# tviibh16m register map
Vendor: Infineon Technologies; Series: TVIIBH16M; File version: 1.0
CPU: CM7 r0p1, little endian, MPU, FPU, double-precision FPU, I-cache, D-cache, VTOR, ITCM, DTCM, 3 interrupt priority bits, 16 interrupts
Registers are 32-bit, read-write, reset 0x0 unless marked. A register's access mark holds for its fields unless they carry their own. Offsets are from the block's base; [hi:lo] are bit positions; lines under a group give offsets from that group; {n}, {i} and the like mark numbered series; 'fields as' and 'values as' point back to an identical list; <NAME> marks a mode.

## SRSS (part 3 of 3) — SRSS Core Registers (ver3p3)
Base 0x40260000
0x1730 CSV_ILO group — CSV registers for HVILO clock
  0x00 CSV group — ILO0 clock DeepSleep domain Clock Supervisor registers
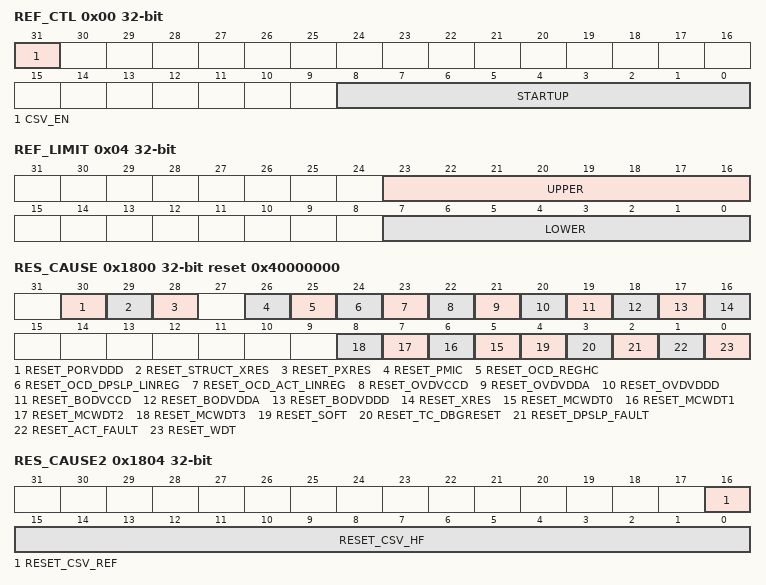
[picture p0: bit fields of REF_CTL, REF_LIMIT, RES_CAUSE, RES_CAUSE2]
    0x00 REF_CTL — Clock Supervision Reference Control
      [31] CSV_EN — Enables clock supervision, both frequency and loss. CSV in Active domain: Clock supervision is reset during DeepSleep and Hibernate modes. When enabled it begins operating automatically after a DeepSleep wakeup, but it must be reconfigured after Hibernate wakeup. CSV in DeepSleep domain: Clock supervision is reset during Hibernate mode. It must be reconfigured after Hibernate wakeup. CSV in Backup domain: Clock supervision operates during Hibernate mode, can be configured to wake from Hibernate, and continues operating during reboot. A CSV error detection is reported to the Fault structure.
      [8:0] STARTUP — Startup delay time -1 (in reference clock cycles), after enable, from reference clock start to monitored clock start. At a minimum (both clocks running): STARTUP >= (PERIOD +3) * FREQ_RATIO - UPPER, with FREQ_RATIO = (Reference frequency / Monitored frequency) On top of that the actual clock startup delay and the margin for accuracy of both clocks must be added.
    0x04 REF_LIMIT — Clock Supervision Reference Limits
      [23:16] UPPER — Cycle time upper limit. Set the upper limit -1, in reference clock cycles, before (or same time) the next monitored clock event must happen. If a monitored clock event does not happen before this limit is reached, or does not happen at all (clock loss), a CSV error is detected.
      [7:0] LOWER — Cycle time lower limit. Set the lower limit -1, in reference clock cycles, before the next monitored clock event is allowed to happen. If a monitored clock event happens before this limit is reached a CSV error is detected. LOWER must be at least 1 less than UPPER. In case the clocks are asynchronous LOWER must be at least 3 less than UPPER.
    0x08 MON_CTL — Clock Supervision Monitor Control
      [7:0] PERIOD — Period time. Set the Period -1, in monitored clock cycles, before the next monitored clock event happens. PERIOD <= (UPPER+1) / FREQ_RATIO -1, with FREQ_RATIO = (Reference frequency / Monitored frequency) In case the clocks are asynchronous: PERIOD <= UPPER / FREQ_RATIO -1 Additionally margin must be added for accuracy of both clocks.
0x1800 RES_CAUSE reset 0x40000000 — Reset Cause Observation Register
  [30] RESET_PORVDDD write-1-clears — Indicator that a POR occurred. This is a high-voltage cause bit, and hardware clears the other bits when this one is set. It does not block further recording of other high-voltage causes.
  [29] RESET_STRUCT_XRES write-1-clears — Structural reset was asserted. This is a high-voltage cause bit that blocks recording of other high-voltage cause bits, except RESET_PORVDDD. Hardware clears this bit during POR. This bit is not blocked by other HV cause bits.
  [28] RESET_PXRES write-1-clears — PXRES triggered. This is a high-voltage cause bit that blocks recording of other high-voltage cause bits, except RESET_PORVDDD. Hardware clears this bit during POR. This bit is not blocked by other HV cause bits.
  [26] RESET_PMIC write-1-clears — PMIC status triggered a reset. PMIC_STATUS_TIMEOUT expiration will set this bit without issuing reset, which will be observed by a subsequent WDT reset. If PMIC control is not present, hardware will never set this bit. This is a high-voltage cause bit that blocks recording of other high-voltage cause bits, except RESET_PORVDDD. Hardware clears this bit during POR.
  [25] RESET_OCD_REGHC write-1-clears — Overcurrent detection from REGHC (if present). REGHC_STATUS_TIMEOUT expiration will set this bit without issuing reset, which will be observed by a subsequent WDT reset. If REGHC is not present, hardware will never set this bit. This is a high-voltage cause bit that blocks recording of other high-voltage cause bits, except RESET_PORVDDD. Hardware clears this bit during POR.
  [24] RESET_OCD_DPSLP_LINREG write-1-clears — Overcurrent detection on the internal VCCD supply when supplied by the DEEPSLEEP power mode linear regulator. This is a high-voltage cause bit that blocks recording of other high-voltage cause bits, except RESET_PORVDDD. Hardware clears this bit during POR.
  [23] RESET_OCD_ACT_LINREG write-1-clears — Overcurrent detection on the internal VCCD supply when supplied by the ACTIVE power mode linear regulator. This is a high-voltage cause bit that blocks recording of other high-voltage cause bits, except RESET_PORVDDD. Hardware clears this bit during POR.
  [22] RESET_OVDVCCD write-1-clears — Overvoltage detection on the internal core VCCD supply. This is a high-voltage cause bit that blocks recording of other high-voltage cause bits, except RESET_PORVDDD. Hardware clears this bit during POR.
  [21] RESET_OVDVDDA write-1-clears — Overvoltage detection on the external VDDA supply. This is a high-voltage cause bit that blocks recording of other high-voltage cause bits, except RESET_PORVDDD. Hardware clears this bit during POR.
  [20] RESET_OVDVDDD write-1-clears — Overvoltage detection on the external VDDD supply. This is a high-voltage cause bit that blocks recording of other high-voltage cause bits, except RESET_PORVDDD. Hardware clears this bit during POR.
  [19] RESET_BODVCCD write-1-clears — Internal VCCD core supply crossed the brown-out limit. Note that this detector will detect gross issues with the internal core supply, but may not catch all brown-out conditions. Functional and timing supervision (CSV, WDT) is provided to create fully failsafe internal crash detection. This is a high-voltage cause bit that blocks recording of other high-voltage cause bits, except RESET_PORVDDD. Hardware clears this bit during POR.
  [18] RESET_BODVDDA write-1-clears — External VDDA supply crossed the brown-out limit. This is a high-voltage cause bit that blocks recording of other high-voltage cause bits, except RESET_PORVDDD. Hardware clears this bit during POR.
  [17] RESET_BODVDDD write-1-clears — External VDDD supply crossed brown-out limit. Note that this cause will only be observable as long as the VDDD supply does not go below the POR (power on reset) detection limit. Below this limit it is not possible to reliably retain information in the device. This is a high-voltage cause bit that blocks recording of other high-voltage cause bits, except RESET_PORVDDD. Hardware clears this bit during POR.
  [16] RESET_XRES write-1-clears — External XRES pin was asserted. This is a high-voltage cause bit that blocks recording of other high-voltage cause bits, except RESET_PORVDDD. Hardware clears this bit during POR. This bit is not blocked by other HV cause bits.
  [n+5] RESET_MCWDT{n} write-1-clears (n=0..3) — Multi-Counter Watchdog timer reset #{n}. This is a low-voltage cause bit that hardware clears when the low-voltage supply is initialized (see comments above).
  [4] RESET_SOFT write-1-clears — A CPU requested a system reset through it's SYSRESETREQ. This can be done via a debugger probe or in firmware. This is a low-voltage cause bit that hardware clears when the low-voltage supply is initialized (see comments above).
  [3] RESET_TC_DBGRESET write-1-clears — Test controller or debugger asserted reset. Only resets debug domain. This is a low-voltage cause bit that hardware clears when the low-voltage supply is initialized (see comments above).
  [2] RESET_DPSLP_FAULT write-1-clears — Fault logging system requested a reset from its DeepSleep logic. This is a low-voltage cause bit that hardware clears when the low-voltage supply is initialized (see comments above).
  [1] RESET_ACT_FAULT write-1-clears — Fault logging system requested a reset from its Active logic. This is a low-voltage cause bit that hardware clears when the low-voltage supply is initialized (see comments above).
  [0] RESET_WDT write-1-clears — A basic WatchDog Timer (WDT) reset has occurred since last power cycle. ULP products: This is a low-voltage cause bit that hardware clears when the low-voltage supply is initialized (see comments above). For products that support high-voltage cause detection, this bit blocks recording of other high-voltage cause bits, except RESET_PORVDDD. Hardware clears this bit during POR. This bit is not blocked by other HV cause bits.
0x1804 RES_CAUSE2 — Reset Cause Observation Register 2
  [16] RESET_CSV_REF write-1-clears — Clock supervision logic requested a reset due to loss or frequency violation of the reference clock source that is used to monitor the other HF clock sources.
  [15:0] RESET_CSV_HF write-1-clears — Clock supervision logic requested a reset due to loss or frequency violation of a high-frequency clock. Each bit index K corresponds to a HFCLK<K>. Unimplemented clock bits return zero.
{0x1900+0x10*i} CLK_PLL400M[{i}] (i=0..1) group — 400MHz PLL Configuration Register
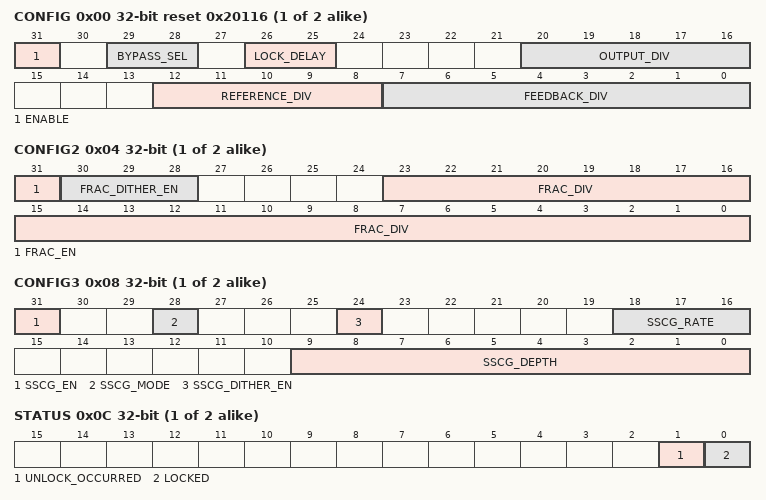
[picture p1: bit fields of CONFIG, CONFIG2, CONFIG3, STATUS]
  0x00 CONFIG reset 0x20116 — 400MHz PLL Configuration Register
    [31] ENABLE — Master enable for PLL. Setup FEEDBACK_DIV, REFERENCE_DIV, and OUTPUT_DIV at least one cycle before setting ENABLE=1. fOUT = (FEEDBACK_DIV + FRAC_EN*FRAC_DIV/2^24) * (fREF / REFERENCE_DIV) / (OUTPUT_DIV) 0: Block is disabled. When the PLL disables, hardware controls the bypass mux as described in BYPASS_SEL, before disabling the PLL circuit. 1: Block is enabled
    [29:28] BYPASS_SEL — Bypass mux located just after PLL output. This selection is glitch-free and can be changed while the PLL is running. When changing BYPASS_SEL, do not turn off the reference clock or PLL clock for five cycles (whichever is slower).
      0=AUTO (Automatic using lock indicator. When unlocked, automatically selects PLL reference input (bypass mode). When locked, automatically selects PLL output. If ENABLE=0, automatically selects PLL reference input.); 1=LOCKED_OR_NOTHING (Similar to AUTO, except the clock is gated off when unlocked. This is compatible with clock supervision, because the supervisors allow no clock during startup (until a timeout occurs), and the clock targets the proper frequency whenever it is running. If ENABLE=0, no clock is output.); 2=PLL_REF (Select PLL reference input (bypass mode). Ignores lock indicator); 3=PLL_OUT (Select PLL output. Ignores lock indicator. If ENABLE=0, no clock is output.)
    [26:25] LOCK_DELAY
    [20:16] OUTPUT_DIV — Control bits for Output divider. Set the divide value before enabling the PLL, and do not change it while PLL is enabled. 0: illegal (undefined behavior) 1: illegal (undefined behavior) 2: divide by 2. Suitable for direct usage as HFCLK source. ... 16: divide by 16. Suitable for direct usage as HFCLK source. >16: illegal (undefined behavior)
    [12:8] REFERENCE_DIV — Control bits for reference divider. Set the divide value before enabling the PLL, and do not change it while PLL is enabled. 0: illegal (undefined behavior) 1: divide by 1 ... 16: divide by 16 others: illegal (undefined behavior) When using fractional mode, the jitter specs are met over the restricted range of 1 to 4, inclusive.
    [7:0] FEEDBACK_DIV — Control bits for feedback divider. Set the divide value before enabling the PLL, and do not change it while PLL is enabled. 0-15: illegal (undefined behavior) 16: divide by 16 ... 200: divide by 200 >200: illegal (undefined behavior) When using fractional mode, the jitter specs are met over the restricted range of 27 to 47, inclusive.
  0x04 CONFIG2 — 400MHz PLL Configuration Register 2
    [31] FRAC_EN — Enables fractional division mode. When using fractional division mode, see CLK_PLL400M_CONFIG.LOCK_DELAY for an additional configuration requirement.
    [30:28] FRAC_DITHER_EN
    [23:0] FRAC_DIV — Control bits for fractional divider. This value is interpreted as a fraction of the PFD frequency, i.e. fPFD * (FRAC_DIV/2^24). This field can be dynamically updated within the 1000ppm control limit. It takes up to 115 AHB cycles to transfer the setting to the PLL, and writes that occur faster may be silently ignored and require the application to write again after the previous update has finished. Reading the register returns the accepted value. The PLL will start targeting the new value, but it may take significant time (milliseconds) to stabilize at the new average value. Do not change the FRAC_DIV setting while the PLL is initially locking.
  0x08 CONFIG3 — 400MHz PLL Configuration Register 3
    [31] SSCG_EN — Enables spreading mode. When using spreading, see CLK_PLL400M_CONFIG.LOCK_DELAY for an additional configuration requirement.
    [28] SSCG_MODE
    [24] SSCG_DITHER_EN
    [18:16] SSCG_RATE
    [9:0] SSCG_DEPTH
  0x0C STATUS — 400MHz PLL Status Register
    [1] UNLOCK_OCCURRED write-1-clears — This bit sets whenever the PLL Lock bit goes low, and stays set until cleared by firmware.
    [0] LOCKED ro — PLL Lock Indicator
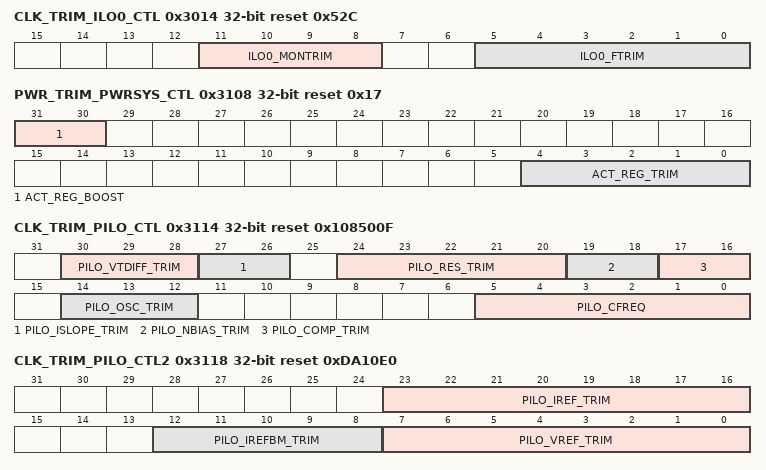
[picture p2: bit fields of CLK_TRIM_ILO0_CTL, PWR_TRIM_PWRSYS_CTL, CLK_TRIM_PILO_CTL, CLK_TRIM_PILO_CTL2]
0x3014 CLK_TRIM_ILO0_CTL reset 0x52C — ILO0 Trim Register
  [11:8] ILO0_MONTRIM — ILO0 internal monitor trim.
  [5:0] ILO0_FTRIM — ILO0 frequency trims. LSB step size is 1.5 percent (typical) of the frequency.
0x3108 PWR_TRIM_PWRSYS_CTL reset 0x17 (reset mask 0x1F) — Power System Trim Register
  [31:30] ACT_REG_BOOST — Controls the tradeoff between output current and internal operating current for the Active Regulator. The maximum output current depends on the silicon implementation, but an application may limit its maximum current to less than that. This may allow a reduction in the internal operating current of the regulator. The regulator internal operating current depends on the boost setting: 2'b00: 50uA 2'b01: 100uA 2'b10: 150uA 2'b11: 200uA The allowed setting is a lookup table based on the chip-specific maximum (set in factory) and an application-specific maximum (set by customer). The defaults are set assuming the application consumes the maximum allowed by the chip. 50mA chip: 2'b00 (default); 100mA chip: 2'b00 (default); 150mA chip: 50..100mA app => 2'b00, 150mA app => 2'b01 (default); 200mA chip: 50mA app => 2'b00, 100..150mA app => 2'b01, 200mA app => 2'b10 (default); 250mA chip: 50mA app => 2'b00, 100..150mA app => 2'b01, 200..250mA app => 2'b10 (default); 300mA chip: 50mA app => 2'b00, 100..150mA app => 2'b01, 200..250mA app => 2'b10, 300mA app => 2'b11 (default); This register is only reset by XRES, HIBERNATE wakeup, or supply supervision reset.
  [4:0] ACT_REG_TRIM — Trim for the Active-Regulator. This sets the output voltage level. This register is only reset by XRES, HIBERNATE wakeup, or supply supervision reset. The nominal output voltage is vccd=812.5mV + ACT_REG_TRIM*12.5mV. The actual output voltage will vary depending on conditions and load. The following settings are explicitly shown for convenience, and other values may be calculated using the formula: 5'h07: 900mV (nominal) 5'h17: 1100mV (nominal)
0x3114 CLK_TRIM_PILO_CTL reset 0x108500F — PILO Trim Register
  [30:28] PILO_VTDIFF_TRIM — Trim for VT-DIFF output (internal power supply)
  [27:26] PILO_ISLOPE_TRIM — Trim for beta-multiplier current slope
  [24:20] PILO_RES_TRIM — Trim for beta-multiplier branch current
  [19:18] PILO_NBIAS_TRIM — Trim for biasn by trimming sub-Vth NMOS width in beta-multiplier
  [17:16] PILO_COMP_TRIM — Trim for comparator bias current.
  [14:12] PILO_OSC_TRIM — Trim for current in oscillator block.
  [5:0] PILO_CFREQ — Coarse frequency trim to meet 32.768kHz +/-2 percent across PVT without calibration. The nominal step size of the LSB is 1kHz.
0x3118 CLK_TRIM_PILO_CTL2 reset 0xDA10E0 — PILO Trim Register 2
  [23:16] PILO_IREF_TRIM — Trim for current reference
  [12:8] PILO_IREFBM_TRIM — Trim for beta-multiplier current reference
  [7:0] PILO_VREF_TRIM — Trim for voltage reference
0x311C CLK_TRIM_PILO_CTL3 reset 0x4800 — PILO Trim Register 3
  [15:0] PILO_ENGOPT — Engineering options for PILO circuits 0: Short vdda to vpwr 1: Beta:mult current change 2: Iref generation Ptat current addition 3: Disable current path in secondary Beta:mult startup circuit 4: Double oscillator current 5: Switch between deep:sub:threshold and sub:threshold stacks in Vref generation block 6: Spare 7: Ptat component increase in Iref 8: vpwr_rc and vpwr_dig_rc shorting testmode 9: Switch b/w psub connection for cascode nfet for vref generation 10: Switch between sub:threshold and deep:sub:threshold stacks in comparator. 15-11: Frequency fine trim. See AKK-444 for an overview of the trim strategy.
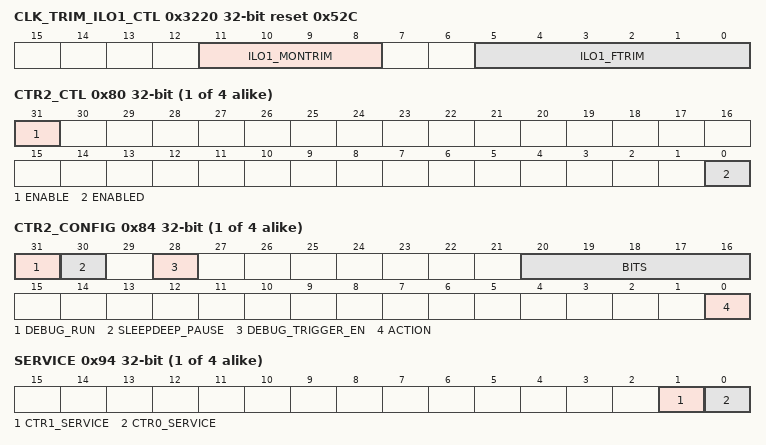
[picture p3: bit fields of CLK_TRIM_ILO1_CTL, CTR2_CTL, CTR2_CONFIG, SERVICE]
0x3220 CLK_TRIM_ILO1_CTL reset 0x52C — ILO1 Trim Register
  [11:8] ILO1_MONTRIM — ILO1 internal monitor trim.
  [5:0] ILO1_FTRIM — ILO1 frequency trims. LSB step size is 1.5 percent (typical) of the frequency.
{0x8000+0x100*i} MCWDT[{i}] (i=0..3) group — Multi-Counter Watchdog Timer
  {0x0+0x20*j} CTR[{j}] (j=0..1) group — MCWDT Configuration for Subcounter 0 and 1
    0x00 CTL — MCWDT Subcounter Control Register
      [31] ENABLE — Enable subcounter. May take up to 2 clk_lf cycles to take effect. When ENABLE changes from 1->0, the counter is cleared. 0: Counter is disabled (not clocked) 1: Counter is enabled (counting up)
      [0] ENABLED ro — Indicates actual state of this subcounter. May lag ENABLE by up to two clk_lf cycles.
    0x04 LOWER_LIMIT — MCWDT Subcounter Lower Limit Register
      [15:0] LOWER_LIMIT — Lower limit for this MCWDT subcounter. See LOWER_ACTION.
    0x08 UPPER_LIMIT — MCWDT Subcounter Upper Limit Register
      [15:0] UPPER_LIMIT — Upper limit for this MCWDT subcounter. See UPPER_ACTION.
    0x0C WARN_LIMIT — MCWDT Subcounter Warn Limit Register
      [15:0] WARN_LIMIT — Warn limit for this MCWDT subcounter. See WARN_ACTION.
    0x10 CONFIG — MCWDT Subcounter Configuration Register
      [31] DEBUG_RUN — Pauses/runs this counter while a debugger is connected. Other behaviors are unchanged during debugging, including service, configuration updates and enable/disable. Note it may take up to two clk_lf cycles for the counter to pause, due to internal synchronization. When (DEBUG_RUN==1 or DEBUG_TRIGGER_EN==0) and the debugger is connected for at least two clk_lf cycles, the LOWER_ACTION is ignored until after the first service after the debugger is disconnected. After the debugger is disconnected, the LOWER_ACTION is ignored until after the first service. This prevents an unintentional trigger of the LOWER_ACTION before the firmware realigns the servicing period. After the first service, LOWER_ACTION behaves as configured. If the debugger is disconnected before two clk_lf cycles, the LOWER_ACTION may or may not be ignored. 0: When debugger connected, counter pauses incrementing as configured in DEBUG_TRIGGER_EN. 1: When debugger connected, counter increments normally, but reset generation is blocked. To block LOWER_ACTION fault generation, write DEBUG_TRIGGER_EN==0.
      [30] SLEEPDEEP_PAUSE — Pauses/runs this counter when the corresponding processor is in SLEEPDEEP. Note it may take up to two clk_lf cycles for the counter to pause and up to two clk_lf cycles for it to unpause, due to internal synchronization. After wakeup, the LOWER_ACTION is ignored until after the first service. This prevents an unintentional trigger of the LOWER_ACTION before the firmware realigns the servicing period. After the first service, LOWER_ACTION behaves as configured. 0: Counter runs normally regardless of processor mode. 1: Counter pauses when corresponding processor is in SLEEPDEEP.
      [28] DEBUG_TRIGGER_EN — Enables the trigger input for this MCWDT to pause the counter during debug mode. To pause at a breakpoint while debugging, configure the trigger matrix to connect the related CPU halted signal to the trigger input for this MCWDT, and then set this bit. It takes up to two clk_lf cycles for the trigger signal to be processed. Triggers that are less than two clk_lf cycles may be missed. Synchronization errors can accumulate each time it is halted. 0: Pauses the counter whenever a debug probe is connected. 1: Pauses the counter whenever a debug probe is connected and the trigger input is high.
      [12] AUTO_SERVICE — Automatically service when the count value reaches WARN_LIMIT. This allows creation of a periodic interrupt if this counter is not needed as a watchdog. This field is ignored when LOWER_ACTION<>NOTHING or when UPPER_ACTION<>NOTHING.
      [8] WARN_ACTION — Action taken when the count value reaches WARN_LIMIT. The minimum setting to achieve a periodic interrupt is WARN_LIMIT==1. A setting of zero will trigger once but not periodically. For WARN_LIMIT >= 2: The action is triggered on same edge when it meets this condition. For WARN_LIMIT == [0,1] : The action may take up to one extra clk_lf cycle to trigger.
        0=NOTHING (Do nothing); 1=INT (Trigger an interrupt.)
      [5:4] UPPER_ACTION — Action taken if this watchdog is not serviced before UPPER_LIMIT is reached. The counter stops counting when UPPER_LIMIT is reached, regardless of UPPER_ACTION setting. UPPER_ACTION is ignored (i.e. treated as NOTHING) when a debugger is connected.
        0=NOTHING (Do nothing); 1=FAULT (Trigger a fault. For UPPER_LIMIT >= 2: The action is triggered on same edge when it meets this condition. For UPPER_LIMIT < 2: The action may take up to one extra clk_lf cycle to trigger.); 2=FAULT_THEN_RESET (Trigger a fault. Further, trigger a system-wide reset if the fault is not serviced and the watchdog is not cleared within 6 clk_lf cycles. It can take up to 3 clk_lf cycles for the fault to be transferred to the fault manager, which gives at least 3 clk_lf cycles for software to respond. For UPPER_LIMIT >= 2: The action is triggered on same edge when it meets this condition. For UPPER_LIMIT < 2: The action may take up to one extra clk_lf cycle to trigger.)
      [1:0] LOWER_ACTION — Action taken if this watchdog is serviced before LOWER_LIMIT is reached. LOWER_ACTION is ignored (i.e. treated as NOTHING) when a debugger is connected and/or when the corresponding processor is in SLEEPDEEP.
        0=NOTHING (Do nothing); 1=FAULT (Trigger a fault. It can take up to 3 clk_lf cycles for the fault to be transferred to the fault manager. For LOWER_LIMIT >= 1: The action is triggered on same edge when it meets this condition. For LOWER_LIMIT == 0: No action is triggered.); 2=FAULT_THEN_RESET (Trigger a fault. Further, trigger a system-wide reset if the fault is not serviced and the watchdog is not cleared within 6 clk_lf cycles. It can take up to 3 clk_lf cycles for the fault to be transferred to the fault manager, which gives at least 3 clk_lf cycles for software to respond. For LOWER_LIMIT >= 1: The action is triggered on same edge when it meets this condition. For LOWER_LIMIT == 0: No action is triggered.)
    0x14 CNT — MCWDT Subcounter Count Register
      [15:0] CNT — Current value of subcounter for this MCWDT. This field may lag the actual count value by up to one clk_lf cycle, due to internal synchronization. When this subcounter is disabled and unlocked, the count value can be written for verification and debugging purposes. Software writes are always ignored when the subcounter is enabled.This register retains information during DeepSleep mode if SLEEPDEEP_PAUSE == 1.
  0x40 CPU_SELECT — MCWDT CPU selection register
    [1:0] CPU_SEL — Assigns this MCWDT to a CPU. This selects which CPU SLEEPDEEP signal is used for SLEEPDEEP_PAUSE.
  0x80 CTR2_CTL — MCWDT Subcounter 2 Control register
    fields as MCWDT[0].CTR[0].CTL
  0x84 CTR2_CONFIG — MCWDT Subcounter 2 Configuration register
    [31] DEBUG_RUN — Pauses/runs this counter while a debugger is connected. Other behaviors are unchanged during debugging, including service, configuration updates and enable/disable. Note it may take up to two clk_lf cycles for the counter to pause and another two cycles to unpause, due to internal synchronization. 0: When debugger connected, counter pauses incrementing as configured in DEBUG_TRIGGER_EN. 1: When debugger connected, counter increments normally, but reset generation is blocked.
    [30] SLEEPDEEP_PAUSE — Pauses/runs this counter when the corresponding processor is in SLEEPDEEP. Note it may take up to two clk_lf cycles for the counter to pause and up to two clk_lf cycles for it to unpause, due to internal synchronization. 0: Counter runs normally regardless of processor mode. 1: Counter pauses when corresponding processor is in SLEEPDEEP.
    [28] DEBUG_TRIGGER_EN — Enables the trigger input for this MCWDT to pause the counter during debug mode. To pause at a breakpoint while debugging, configure the trigger matrix to connect the related CPU halted signal to the trigger input for this MCWDT, and then set this bit. It takes up to two clk_lf cycles for the trigger signal to be processed. Triggers that are less than two clk_lf cycles may be missed. Synchronization errors can accumulate each time it is halted. 0: Pauses the counter whenever a debug probe is connected. 1: Pauses the counter whenever a debug probe is connected and the trigger input is high.
    [20:16] BITS — Bit to observe for a toggle: 0: Do ACTION after CNT[0] toggles (i.e. every tick) . 31: Do ACTION after CNT[31] toggles (i.e. every 2^31 ticks)
    [0] ACTION — Action taken when the specified BIT toggles. Action will be triggered on the same edge where BITS to observe toggle.
      0=NOTHING (Do nothing); 1=INT (Trigger an interrupt)
  0x88 CTR2_CNT — MCWDT Subcounter 2 Count Register
    [31:0] CNT2 — Current value of subcounter 2 for this MCWDT. This field may lag the actual count value by up to one clk_lf cycle, due to internal synchronization. When this subcounter is disabled and unlocked, the count value can be written for verification and debugging purposes. Software writes are always ignored when the subcounter is enabled. This register retains information during DeepSleep mode if SLEEPDEEP_PAUSE == 1.
  0x90 LOCK — MCWDT Lock Register
    [1:0] MCWDT_LOCK — Prohibits writing control and configuration registers related to this MCWDT when not equal 0 (as specified in the other register descriptions). Requires at least two different writes to unlock. Note that this field is 2 bits to force multiple writes only. Each MCWDT has a separate local lock.
      0=NO_CHG (No effect); 1=CLR0 (Clears bit 0); 2=CLR1 (Clears bit 1); 3=SET01 (Sets both bits 0 and 1)
  0x94 SERVICE — MCWDT Service Register
    [1] CTR1_SERVICE write-1-sets — Services subcounter 1. This resets the count value for subcounter 1 to zero. This may take up to three clk_lf cycles to take effect. Hardware clears this bit, after necessary synchronization. To ensure a pending CTR1_SERVICE write is reflected, firmware should wait until this bit reads low before attempting to write CTR1_SERVICE=1. If subcounter 1 is disabled, CTR1_SERVICE will not trigger a LOWER_ACTION and will not clear a preloaded count value.
    [0] CTR0_SERVICE write-1-sets — Services subcounter 0. This resets the count value for subcounter 0 to zero. This may take up to three clk_lf cycles to take effect. Hardware clears this bit, after necessary synchronization. To ensure a pending CTR0_SERVICE write is reflected, firmware should wait until this bit reads low before attempting to write CTR0_SERVICE=1. If subcounter 0 is disabled, CTR0_SERVICE will not trigger a LOWER_ACTION and will not clear a preloaded count value.
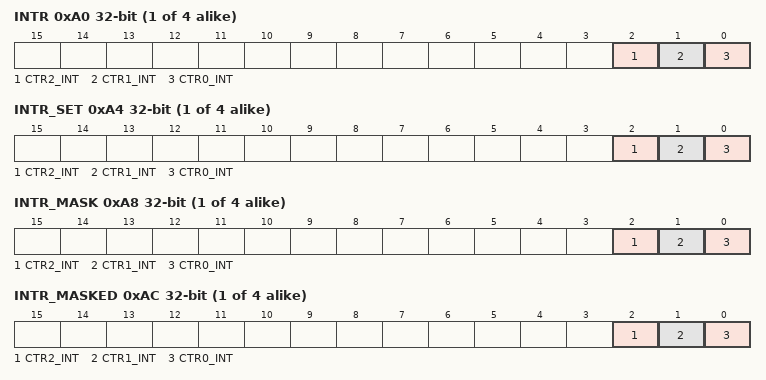
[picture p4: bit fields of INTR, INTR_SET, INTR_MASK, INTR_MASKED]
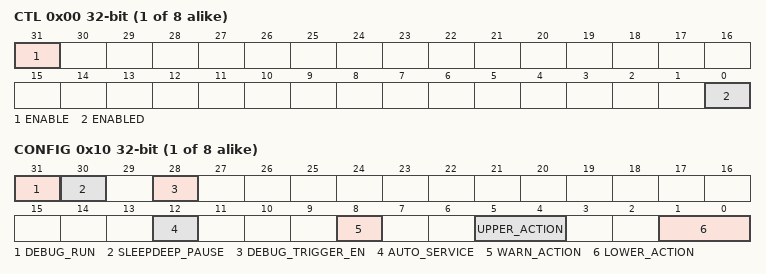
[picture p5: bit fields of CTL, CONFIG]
  0xA0 INTR — MCWDT Interrupt Register
    [2] CTR2_INT write-1-clears — MCWDT Interrupt Request for sub-counter 2. This bit is set by hardware as configured by this registers. This bit must be cleared by firmware.
    [1] CTR1_INT write-1-clears — MCWDT Interrupt Request for sub-counter 1. This bit is set by hardware as configured by this registers. This bit must be cleared by firmware.
    [0] CTR0_INT write-1-clears — MCWDT Interrupt Request for sub-counter 0. This bit is set by hardware as configured by this registers. This bit must be cleared by firmware.
  0xA4 INTR_SET — MCWDT Interrupt Set Register
    [2] CTR2_INT write-1-sets — Set interrupt for MCWDT_INT2
    [1] CTR1_INT write-1-sets — Set interrupt for MCWDT_INT1
    [0] CTR0_INT write-1-sets — Set interrupt for MCWDT_INT0
  0xA8 INTR_MASK — MCWDT Interrupt Mask Register
    [2] CTR2_INT — Interrupt Mask for sub-counter 2. The bit controls if the interrupt is forwarded to the CPU. The interrupt is blocked when the value of the bit is 0. The interrupt is forwarded if the value of the bit is 1.
    [1] CTR1_INT — Interrupt Mask for sub-counter 1 for warning interrupt. The bit controls if the interrupt is forwarded to the CPU. The interrupt is blocked when the value of the bit is 0. The interrupt is forwarded if the value of the bit is 1.
    [0] CTR0_INT — Interrupt Mask for sub-counter 0 for warning interrupt. The bit controls if the interrupt is forwarded to the CPU. The interrupt is blocked when the value of the bit is 0. The interrupt is forwarded if the value of the bit is 1.
  0xAC INTR_MASKED ro — MCWDT Interrupt Masked Register
    [2] CTR2_INT — Logical and of corresponding request and mask bits.
    [1] CTR1_INT — Logical and of corresponding request and mask bits.
    [0] CTR0_INT — Logical and of corresponding request and mask bits.
0xC000 WDT group — Watchdog Timer
  0x00 CTL reset 0x80000001 — WDT Control Register
    [31] ENABLE — Enable watchdog. May take up to three clk_ilo0 cycles to take effect. When ENABLE changes from 1->0, the counter is cleared. Do not enter DEEPSLEEP or HIBERNATE mode if ENABLE<>ENABLED. This can be done by waiting until ENABLE==ENABLED whenever ENABLE is changed. 0: Counter is disabled (not clocked). 1: Counter is enabled (counting up)
    [0] ENABLED ro — Indicates actual state of watchdog. May lag ENABLE by up to three clk_ilo0 cycles.
  0x04 LOWER_LIMIT — WDT Lower Limit Register
    [31:0] LOWER_LIMIT — Lower limit for watchdog. See LOWER_ACTION.
  0x08 UPPER_LIMIT reset 0x8000 — WDT Upper Limit Register
    [31:0] UPPER_LIMIT — Upper limit for watchdog. See UPPER_ACTION.
  0x0C WARN_LIMIT — WDT Warn Limit Register
    [31:0] WARN_LIMIT — Warn limit for watchdog. See WARN_ACTION.
  0x10 CONFIG reset 0x10 — WDT Configuration Register
    [31] DEBUG_RUN — Pauses/runs this counter while a debugger is connected. Other behaviors are unchanged during debugging, including service, configuration updates and enable/disable. Note it may take up to two clk_ilo0 cycles for the counter to pause and another two cycles to unpause, due to internal synchronization. If the debugger is connected for at least two clk_ilo0 cycles, the LOWER_ACTION is ignored until after the first service after the debugger is disconnected. This prevents an unintentional trigger of the LOWER_ACTION before the firmware realigns the servicing period. After the first service, LOWER_ACTION behaves as configured. If the debugger is disconnected before two clk_ilo0 cycles, the LOWER_ACTION may or may not be ignored. 0: When debugger connected, counter pauses incrementing as configured in DEBUG_TRIGGER_EN. 1: When debugger connected, counter increments normally, but reset generation is blocked.
    [30] HIB_PAUSE — Pauses/runs this counter when the system is in HIBERNATE. Note it may take up to two clk_ilo0 cycles for the counter to pause, due to internal synchronization. After wakeup, the LOWER_ACTION is ignored until after the first service. This prevents an unintentional trigger of the LOWER_ACTION before the firmware realigns the servicing period. After the first service, LOWER_ACTION behaves as configured. 0: Counter behaves normally during HIBERNATE. 1: Counter pauses during HIBERNATE.
    [29] DPSLP_PAUSE — Pauses/runs this counter when the system is in DEEPSLEEP. Note it may take up to two clk_ilo0 cycles for the counter to pause, due to internal synchronization. During DEEPSLEEP wakeup, the pause request is removed when clk_hf0 starts clocking, and then it may take up to two clk_ilo0 cycles for the counter to start. After wakeup, the LOWER_ACTION is ignored until after the first service. This prevents an unintentional trigger of the LOWER_ACTION before the firmware realigns the servicing period. After the first service, LOWER_ACTION behaves as configured. 0: Counter behaves normally during DEEPSLEEP. 1: Counter pauses during DEEPSLEEP.
    [28] DEBUG_TRIGGER_EN — Enables the trigger input for WDT to pause the counter during debug mode. To pause at a breakpoint while debugging, configure the trigger matrix to connect the related CPU halted signal to the trigger input for this WDT, and then set this bit. It takes up to two clk_ilo0 cycles for the trigger signal to be processed. Triggers that are less than two clk_ilo0 cycles may be missed. Synchronization error can accumulate each time it is halted. 0: Pauses the counter whenever a debug probe is connected. 1: Pauses the counter whenever a debug probe is connected and the trigger input is high.
    [12] AUTO_SERVICE — Automatically service when the count value reaches WARN_LIMIT. This allows creation of a periodic interrupt if this counter is not needed as a watchdog. This field is ignored when LOWER_ACTION<>NOTHING or when UPPER_ACTION<>NOTHING.
    [8] WARN_ACTION — Action taken when the count value reaches WARN_LIMIT. The minimum setting to achieve a periodic interrupt is WARN_LIMIT==1. A setting of zero will trigger once but not periodically. For WARN_LIMIT >= 2: The action is triggered on same edge when it meets this condition. For WARN_LIMIT < 2 : The action may take up to one extra clk_ilo0 cycle to trigger.
      0=NOTHING (Do nothing); 1=INT (Trigger an interrupt.)
    [4] UPPER_ACTION — Action taken if this watchdog is not serviced before UPPER_LIMIT is reached. The counter stops counting when UPPER_LIMIT is reached, regardless of UPPER_ACTION setting. UPPER_ACTION is ignored (i.e. treated as NOTHING) when a debugger is connected. For UPPER_LIMIT >= 2: The action is triggered on same edge when it meets this condition. For UPPER_LIMIT < 2: The action may take up to one extra clk_ilo0 cycle to trigger.
      0=NOTHING (Do nothing); 1=RESET (Trigger a reset.)
    [0] LOWER_ACTION — Action taken if this watchdog is serviced before LOWER_LIMIT is reached. LOWER_ACTION is ignored (i.e. treated as NOTHING) when a debugger is connected and/or when the chip is in DEEPSLEEP/HIBERNATE modes. For LOWER_LIMIT >= 1: The action is triggered on same edge when it meets this condition. For LOWER_LIMIT == 0: No action is triggered.
      0=NOTHING (Do nothing); 1=RESET (Trigger a reset.)
  0x14 CNT — WDT Count Register
    [31:0] CNT — Current value of subcounter for this WDT. This field may lag the actual count value by up to one clk_ilo0 cycle, due to internal synchronization. When this subcounter is disabled and unlocked, the count value can be written for verification and debugging purposes. Software writes are always ignored when the subcounter is enabled. This register retains information during DeepSleep or Hiberbate mode if DPSLP_PAUSE == 1 or HIB_PAUSE == 1.
  0x40 LOCK reset 0x3 — WDT Lock register
    [1:0] WDT_LOCK — Prohibits writing control and configuration registers related to this WDT when not equal 0 (as specified in the other register descriptions). Requires at least two different writes to unlock. Note that this field is 2 bits to force multiple writes only. This register also locks the clk_ilo0 settings.
      values as MCWDT[0].LOCK.MCWDT_LOCK
  0x44 SERVICE — WDT Service register
    [0] SERVICE write-1-sets — Services the watchdog. This resets the count value to zero. This may take up to three clk_ilo0 cycle to take effect. Hardware clears this bit, after necessary synchronization. To ensure a pending SERVICE write is reflected, firmware should wait until this bit reads low before attempting to write SERVICE=1. If WDT is disabled, SERVICE will not trigger a LOWER_ACTION and will not clear a preloaded count value.
  0x50 INTR — WDT Interrupt Register
    [0] WDT write-1-clears — WDT Interrupt Request. This bit is set as configured by WDT action and limits. Due to internal synchronization, it takes up to 8 SYSCLK cycles to update after a W1C or reading this register and during this time AHB bus is stalled.
  0x54 INTR_SET — WDT Interrupt Set Register
    [0] WDT write-1-sets — Set interrupt. Due to internal synchronization, it takes up to 8 SYSCLK cycles to update after a W1S or reading from this register and during this time AHB bus is stalled.
  0x58 INTR_MASK — WDT Interrupt Mask Register
    [0] WDT — Mask for watchdog timer. Clearing this bit will not forward the interrupt to the CPU.
  0x5C INTR_MASKED ro — WDT Interrupt Masked Register
    [0] WDT — Logical and of corresponding request and mask bits. Due to internal synchronization, it takes up to 8 SYSCLK cycles to read from this register. During this time AHB bus is stalled.
